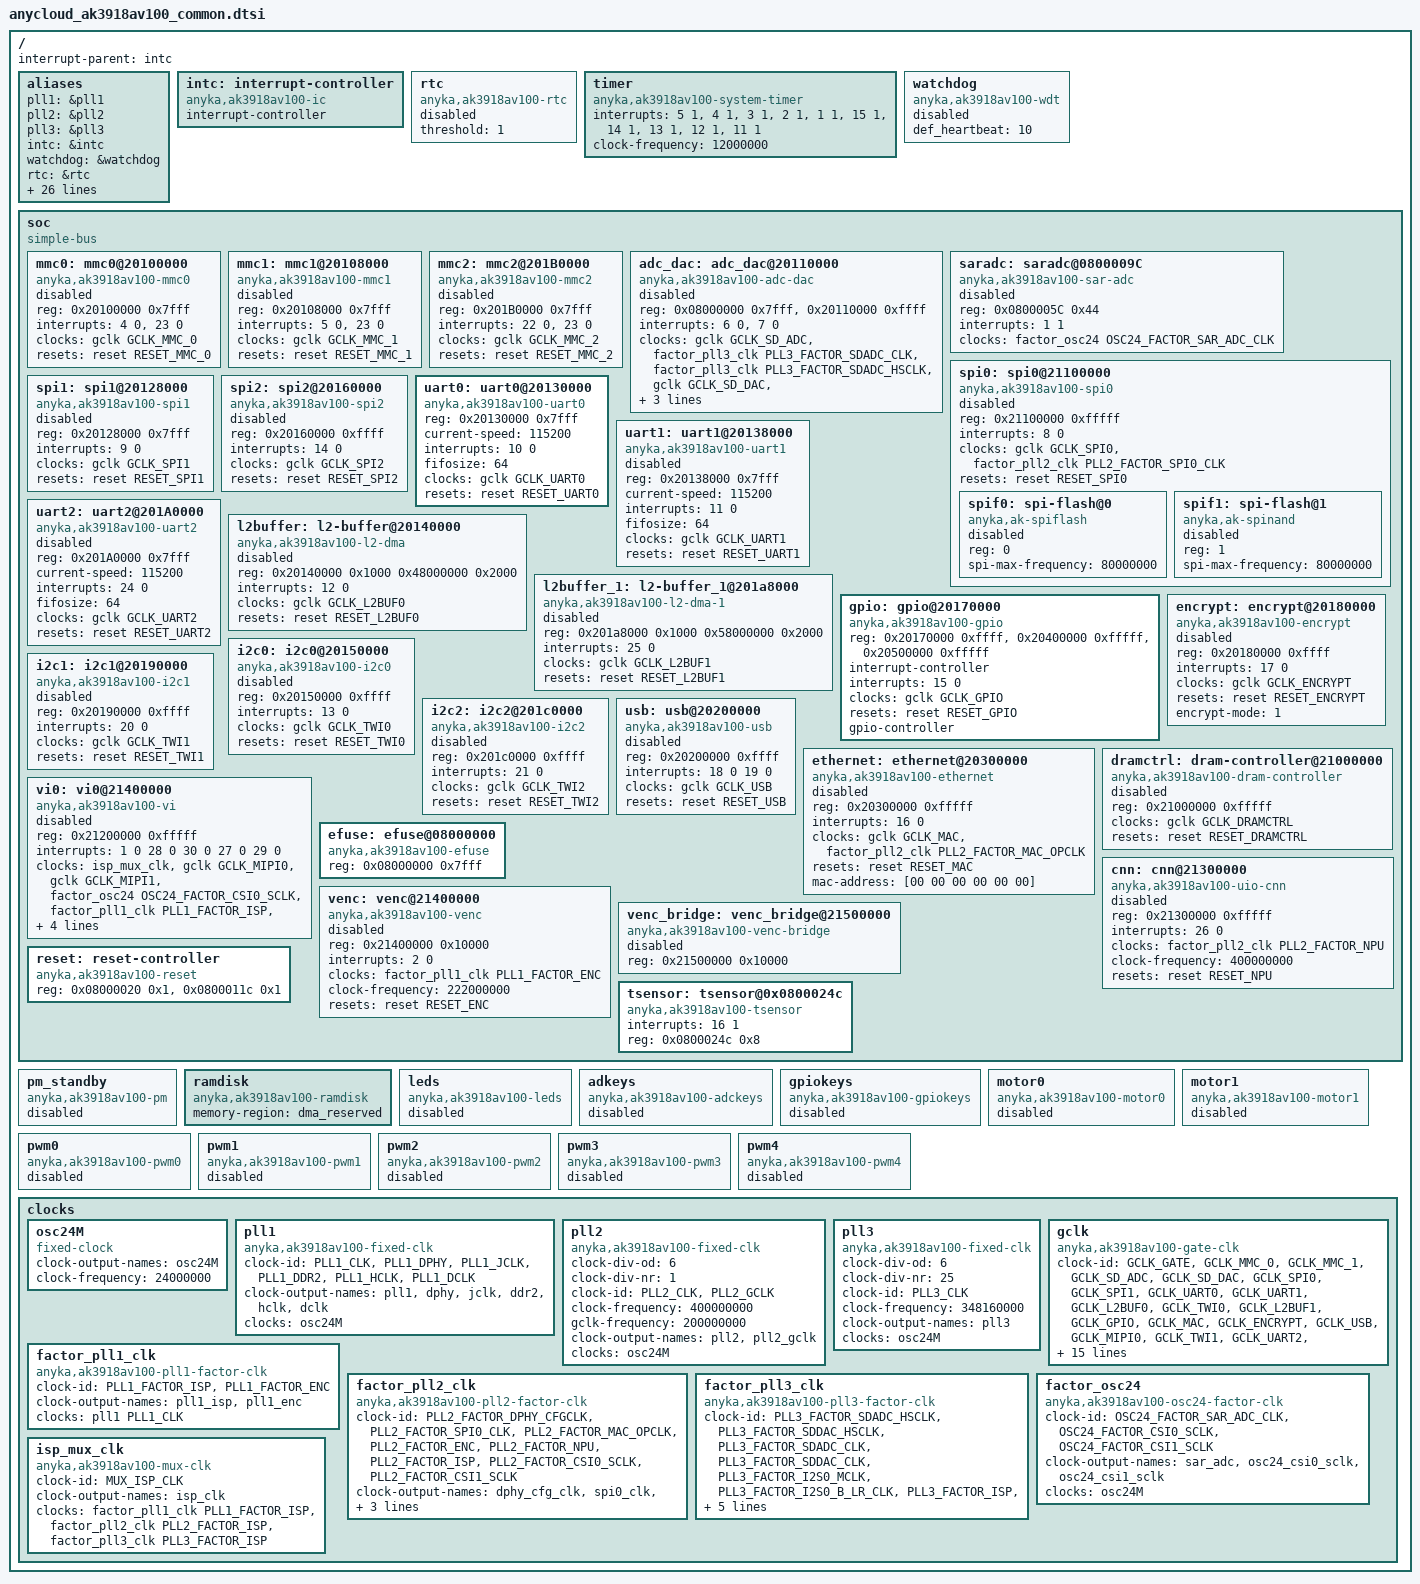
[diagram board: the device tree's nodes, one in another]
/*
 * ak3918av100 SoC
 *
 * Copyright (C) 2018 Anyka(Guangzhou) Microelectronics Technology Co., Ltd.
 *
 * This program is free software; you can redistribute it and/or modify
 * it under the terms of the GNU General Public License as published by
 * the Free Software Foundation; either version 2 of the License, or
 * (at your option) any later version.
 *
 * This program is distributed in the hope that it will be useful,
 * but WITHOUT ANY WARRANTY; without even the implied warranty of
 * MERCHANTABILITY or FITNESS FOR A PARTICULAR PURPOSE.  See the
 * GNU General Public License for more details.
 */
#include <dt-bindings/gpio/gpio.h>
#include <dt-bindings/clock/ak3918av100_clock.h>
#include <dt-bindings/hwmon/ina2xx.h>

/ {
    #address-cells = <1>;
    #size-cells = <1>;

    interrupt-parent = <&intc>;

    aliases {
        pll1 = &pll1;
        pll2 = &pll2;
        pll3 = &pll3;
        intc = &intc;
        watchdog = &watchdog;
        rtc = &rtc;
        pwm0 = &pwm0;
        pwm1 = &pwm1;
        pwm2 = &pwm2;
        pwm3 = &pwm3;
        pwm4 = &pwm4;
        gpio = &gpio;
        uart0 = &uart0;
        uart1 = &uart1;
        uart2 = &uart2;
        spi0 = &spi0;
        spi1 = &spi1;
        spi2 = &spi2;
        mmc0 = &mmc0;
        mmc1 = &mmc1;
        mmc2 = &mmc2;
        i2c0 = &i2c0;
        i2c1 = &i2c1;
        i2c2 = &i2c2;
        motor0 = &motor0;
        motor1 = &motor1;
        usb = &usb;
        leds = &leds;
        adkeys = &adkeys;
        gpiokeys = &gpiokeys;
        ethernet0 = &ethernet;
        pm_standby = &pm_standby;
    };

    intc: interrupt-controller {
        compatible = "anyka,ak3918av100-ic";
        interrupt-controller;
        #interrupt-cells = <2>;
    };

    rtc: rtc {
        compatible = "anyka,ak3918av100-rtc";
		/*
		 * under_voltage_detection
		 * 
		 * threshold:
		 * 0: reset when VDDIO drops below 2.79V,
		 *     and the reset will be deasserted when VDDIO reaches 3.0V
		 * 1: reset when VDDIO drops below 2.65V,
		 *     and the reset will be deasserted when VDDIO reaches 2.86V
		 * 2: reset when VDDIO drops below 2.55V,
		 *     and the reset will be deasserted when VDDIO reaches 2.78V
		 * 3: reset when VDDIO drops below 2.46V,
		 *     and the reset will be deasserted when VDDIO reaches 2.68V
		 */
		threshold = <1>;
        status = "disable";
    };

    timer {
        compatible = "anyka,ak3918av100-system-timer";
        interrupts = <5 1>,  // timer0, TOP_INT Interrupt Mask (Address: 0x0800,002C) bit5
                     <4 1>,  // timer1, TOP_INT Interrupt Mask (Address: 0x0800,002C) bit4
                     <3 1>,  // timer2, TOP_INT Interrupt Mask (Address: 0x0800,002C) bit3
                     <2 1>,  // timer3, TOP_INT Interrupt Mask (Address: 0x0800,002C) bit2
                     <1 1>,  // timer4, TOP_INT Interrupt Mask (Address: 0x0800,002C) bit1
                     <15 1>, // timer5, TOP_INT Interrupt Mask (Address: 0x0800,002C) bit15
                     <14 1>, // timer6, TOP_INT Interrupt Mask (Address: 0x0800,002C) bit14
                     <13 1>, // timer7, TOP_INT Interrupt Mask (Address: 0x0800,002C) bit13
                     <12 1>, // timer8, TOP_INT Interrupt Mask (Address: 0x0800,002C) bit12
                     <11 1>; // timer9, TOP_INT Interrupt Mask (Address: 0x0800,002C) bit11
        clock-frequency = <12000000>;
        status = "okay";
    };

    watchdog: watchdog {
        compatible = "anyka,ak3918av100-wdt";
        /*max feed dog time = 357s, default setting time = 10s. */
        def_heartbeat = <10>;
        status = "disable";
    };

    soc: soc {
        compatible = "simple-bus";
        #address-cells = <1>;
        #size-cells = <1>;
        ranges;

        mmc0: mmc0@20100000 {
            compatible = "anyka,ak3918av100-mmc0";
            reg = <0x20100000 0x7fff>;
            /* 
             * Bank0
             * 0x08000024 bit[4]    MCI/SD/SDIO Controller 0 Interrupt
             * 0x08000024 bit[23]   SD Plugin-Plugoff Interrupt
             */
            interrupts = <4 0>,<23 0>;
            clocks = <&gclk GCLK_MMC_0>;
            clock-names   = "mmc0";
            resets	  = <&reset RESET_MMC_0>;
            reset-names   = "mmc0"; /* same as node name */
            status = "disable";
        };

        mmc1: mmc1@20108000 {
            compatible = "anyka,ak3918av100-mmc1";
            /* 
             * Bank0
             * 0x08000024 bit[5]    MCI/SD/SDIO Controller 1 Interrupt
             * 0x08000024 bit[23]   SD Plugin-Plugoff Interrupt
             */
            reg = <0x20108000 0x7fff>;
            interrupts = <5 0>, <23 0>;
            clocks = <&gclk GCLK_MMC_1>;
            clock-names   = "mmc1_gclk";
            resets	  = <&reset RESET_MMC_1>;
            reset-names   = "mmc1"; /* same as node name */
            status = "disable";
        };

        mmc2: mmc2@201B0000 {
            compatible = "anyka,ak3918av100-mmc2";
            reg = <0x201B0000 0x7fff>;
            /* 
             * Bank0
             * 0x08000024 bit[22]    MCI/SD/SDIO Controller 2 Interrupt
             * 0x08000024 bit[23]   SD Plugin-Plugoff Interrupt
             */
            interrupts = <22 0>,<23 0>;
            clocks = <&gclk GCLK_MMC_2>;
            clock-names   = "mmc2_gclk";
            resets	  = <&reset RESET_MMC_2>;
            reset-names   = "mmc2"; /* same as node name */
            status = "disable";
        };

        adc_dac: adc_dac@20110000 {
            compatible = "anyka,ak3918av100-adc-dac";
            reg = <0x08000000 0x7fff>,
                  <0x20110000 0xffff>;
             /* 
             * Bank0
             * 0x08000024 bit[6]  Audio DAC Controller Interrupt
             * 0x08000024 bit[7] Audio ADC Controller Interrupt
             */
            interrupts = <6 0>,<7 0>;
            clocks =
                <&gclk GCLK_SD_ADC>,          //sdadc_gclk
                <&factor_pll3_clk PLL3_FACTOR_SDADC_CLK>,   //sdadc_clk
                <&factor_pll3_clk PLL3_FACTOR_SDADC_HSCLK>,   //sdadchs_clk
                <&gclk GCLK_SD_DAC>,          //sddac_gclk
                <&factor_pll3_clk PLL3_FACTOR_SDDAC_CLK>,   //sddac_clk
                <&factor_pll3_clk PLL3_FACTOR_SDDAC_HSCLK>;   //sddachs_clk
  
            clock-names =
                "sdadc_gclk",
                "sdadc_clk",
                "sdadchs_clk",
                "sddac_gclk",
                "sddac_clk",
                "sddachs_clk";

            resets = <&reset RESET_SD_ADC>,
                     <&reset RESET_SD_DAC>;
            reset-names   = "sdadc",
                            "sddac";
          
            status = "disable";
        };

        saradc: saradc@0800009C {
            compatible = "anyka,ak3918av100-sar-adc";
            reg = <0x0800005C 0x44>;
            /*
             * Bank1
             * 0x0800002c [0]:sar_adc_int_en 
             */
            interrupts = <1 1>;
            clocks = <&factor_osc24 OSC24_FACTOR_SAR_ADC_CLK>;
            status = "disable";
        };
        
        spi0: spi0@21100000 {
            compatible = "anyka,ak3918av100-spi0";
            reg = <0x21100000 0xfffff>;
            /*
             * Bank0
             * 0x08000024 [8] SFC --- Fast SPI
             */
            interrupts = <8 0>;
            clocks = <&gclk GCLK_SPI0>,
                     <&factor_pll2_clk PLL2_FACTOR_SPI0_CLK>;
            clock-names = "spi0_gclk",
                          "spi0_bus"; 

            resets = <&reset RESET_SPI0>;
            reset-names   = "spi0";

            #address-cells = <1>;
            #size-cells = <0>;
            status = "disable";

            spif0:spi-flash@0 {
                compatible = "anyka,ak-spiflash";
                reg = <0>; /* Chip select 0 */
                spi-max-frequency = <80000000>;
                status = "disable";
                #address-cells = <1>;
                #size-cells = <0>;
            };

            spif1:spi-flash@1 {
                compatible = "anyka,ak-spinand";
                reg = <1>; /* Chip select 1 */
                spi-max-frequency = <80000000>;
                status = "disable";
            };
        };

        spi1: spi1@20128000 {
            compatible = "anyka,ak3918av100-spi1";
            reg = <0x20128000 0x7fff>;
            /*
             * Bank0
             * 0x08000024 [9] SPI 1 Interrupt
             */
            interrupts = <9 0>;
            clocks = <&gclk GCLK_SPI1>;
            clock-names = "spi1_gclk";
            resets = <&reset RESET_SPI1>;
            reset-names   = "spi1";

            #address-cells = <1>;
            #size-cells = <0>;
            status = "disable";
        };

        spi2: spi2@20160000 {
            compatible = "anyka,ak3918av100-spi2";
            reg = <0x20160000 0xffff>;
            /*
             * Bank0
             * 0x08000024 [14] SPI 2 Interrupt
             */
            interrupts = <14 0>;
            clocks = <&gclk GCLK_SPI2>;
            clock-names = "spi2_gclk";
            resets = <&reset RESET_SPI2>;
            reset-names   = "spi2";

            #address-cells = <1>;
            #size-cells = <0>;
            status = "disable";
        };

        uart0: uart0@20130000 {
            compatible = "anyka,ak3918av100-uart0";
            reg = <0x20130000 0x7fff>;
            current-speed = <115200>;
            /*
             * Bank0
             * 0x08000024 [10] UART 0 Interrupt
             */
            interrupts = <10 0>;
            fifosize = <64>;

            clocks = <&gclk GCLK_UART0>;
            clock-names = "uart0_gclk";
            resets = <&reset RESET_UART0>;
            reset-names   = "uart0";
            
            status = "okay";
        };

        uart1: uart1@20138000 {
            compatible = "anyka,ak3918av100-uart1";
            reg = <0x20138000 0x7fff>;
            current-speed = <115200>;
            /*
             * Bank0
             * 0x08000024 [11] UART 1 Interrupt
             */
            interrupts = <11 0>;
            fifosize = <64>;

            clocks = <&gclk GCLK_UART1>;
            clock-names = "uart1_gclk";
            resets = <&reset RESET_UART1>;
            reset-names   = "uart1";

            status = "disable";
        };

        uart2: uart2@201A0000 {
            compatible = "anyka,ak3918av100-uart2";
            reg = <0x201A0000 0x7fff>;
            current-speed = <115200>;
            /*
             * Bank0
             * 0x08000024 [24] UART 2 Interrupt
             */
            interrupts = <24 0>;
            fifosize = <64>;

            clocks = <&gclk GCLK_UART2>;
            clock-names = "uart2_gclk";
            resets = <&reset RESET_UART2>;
            reset-names   = "uart2";

            status = "disable";
        };

        l2buffer: l2-buffer@20140000 {
            compatible = "anyka,ak3918av100-l2-dma";
            reg = <0x20140000 0x1000
                   0x48000000 0x2000>;
            /*
             * Bank0
             * 0x08000024 [12] L2-Buffer0 Interrupt
             */
            interrupts = <12 0>;
            
            clocks = <&gclk GCLK_L2BUF0>;
            clock-names = "l2buffer0_gclk";
            resets = <&reset RESET_L2BUF0>;
            reset-names   = "l2buffer0";

            status = "disable";
        };
        
        l2buffer_1: l2-buffer_1@201a8000 {
            compatible = "anyka,ak3918av100-l2-dma-1";
            reg = <0x201a8000 0x1000
                   0x58000000 0x2000>;
            /*
             * Bank0
             * 0x08000024 [25] L2-Buffer1 Interrupt
             */
            interrupts = <25 0>;

            clocks = <&gclk GCLK_L2BUF1>;
            clock-names = "l2buffer1_gclk";
            resets = <&reset RESET_L2BUF1>;
            reset-names   = "l2buffer_1";

            status = "disable";
        };

        gpio: gpio@20170000 {
            compatible = "anyka,ak3918av100-gpio";
            reg = <0x20170000 0xffff>,
            <0x20400000 0xfffff>,    /* mipi0 */
            <0x20500000 0xfffff>;    /* mipi1 */

            interrupt-controller;
            #interrupt-cells = <2>;
            /*
             * Bank0
             * 0x08000024 [15] GPIO Interrupt
             */
            interrupts = <15 0>;

            clocks = <&gclk GCLK_GPIO>;
            clock-names = "gpio_gclk";
            resets = <&reset RESET_GPIO>;
            reset-names   = "gpio";

            gpio-controller;
            #gpio-cells = <2>;
            status = "okay";
        };

        encrypt: encrypt@20180000 {
            compatible = "anyka,ak3918av100-encrypt";
            reg = <0x20180000 0xffff>;
            interrupts = <17 0>;
  
            clocks = <&gclk GCLK_ENCRYPT>;
            clock-names = "encrypt_gclk";
            resets = <&reset RESET_ENCRYPT>;
            reset-names   = "encrypt";

            /*
            * encrypt-mode
            * 0 = CRYPTO_SINGLE_GROUP_MODE ; 1 = CRYPTO_MULTI_GROUP_MODE
            */
            encrypt-mode = <1>;
            
            status = "disable";
        };

        i2c0: i2c0@20150000 {
            compatible = "anyka,ak3918av100-i2c0";
            reg = <0x20150000 0xffff>;
            /*
             * Bank0
             * 0x08000024 [13] I2C 0 Interrupt
             */
            interrupts = <13 0>;

            clocks = <&gclk GCLK_TWI0>;
            clock-names = "i2c0_gclk";
            resets = <&reset RESET_TWI0>;
            reset-names   = "i2c0";

            status = "disable";
        };

        i2c1: i2c1@20190000 {
            compatible = "anyka,ak3918av100-i2c1";
            reg = <0x20190000 0xffff>;
            /*
             * Bank0
             * 0x08000024 [20] I2C 1 Interrupt
             */
            interrupts = <20 0>;

            clocks = <&gclk GCLK_TWI1>;
            clock-names = "i2c1_gclk";
            resets = <&reset RESET_TWI1>;
            reset-names   = "i2c1";

            status = "disable";
        };

        i2c2: i2c2@201c0000 {
            compatible = "anyka,ak3918av100-i2c2";
            reg = <0x201c0000 0xffff>;
            /*
             * Bank0
             * 0x08000024 [21] I2C 2 Interrupt
             */          
            interrupts = <21 0>;

            clocks = <&gclk GCLK_TWI2>;
            clock-names = "i2c2_gclk";
            resets = <&reset RESET_TWI2>;
            reset-names   = "i2c2";

            #address-cells = <1>;
            #size-cells = <0>;
            status = "disable";
        };

        usb: usb@20200000 {
            compatible = "anyka,ak3918av100-usb";
            reg = <0x20200000 0xffff>;
            /*
             * Bank0
             * 0x08000024 [18] USB CPU Interrupt
             * 0x08000024 [19] USB DMA Interrupt
             */  
            interrupts = <18 0
                          19 0>;

            clocks = <&gclk GCLK_USB>;
            clock-names = "usb_gclk";
            resets = <&reset RESET_USB>;
            reset-names   = "usb";

            status = "disable";
        };

        ethernet: ethernet@20300000 {
            compatible = "anyka,ak3918av100-ethernet";
            reg = <0x20300000 0xfffff>;
            /*
             * Bank0
             * 0x08000024 [16] MAC Interrupt
             */  
            interrupts = <16 0>;
           
            clocks = <&gclk GCLK_MAC>,
                     <&factor_pll2_clk PLL2_FACTOR_MAC_OPCLK>; 
            clock-names = "mac_gclk", "mac0_opclk";
            resets = <&reset RESET_MAC>;
            reset-names   = "mac";

            mac-address = [00 00 00 00 00 00];
            status = "disable";
        };

        dramctrl:dram-controller@21000000 {
            compatible = "anyka,ak3918av100-dram-controller";
            reg = <0x21000000 0xfffff>;

            clocks = <&gclk GCLK_DRAMCTRL>;
            clock-names = "dramctrl_gclk";
            resets = <&reset RESET_DRAMCTRL>;
            reset-names   = "dramctrl";

            status = "disable";
        };

        vi0: vi0@21400000 {
            compatible = "anyka,ak3918av100-vi";
            reg = <0x21200000 0xfffff>;	/*image capreture controller*/
            /*
             * Bank0
             * 0x08000024 [1] ISP Interrupt
             * 0x08000024 [28] CSI0 normal Interrupt
             * 0x08000024 [30] CSI0 error occur Interrupt
             * 0x08000024 [27] CSI1 normal Interrupt
             * 0x08000024 [29] CSI1 error occur Interrupt
             */ 
            interrupts = <1 0
                          28 0
                          30 0
                          27 0
                          29 0>;
            clocks =  
                      /*<&factor_pll3_clk  PLL3_FACTOR_ISP>,*/
                      /*<&factor_pll2_clk  PLL2_FACTOR_ISP>,*/
                      <&isp_mux_clk>,
                      <&gclk GCLK_MIPI0>,
                      <&gclk GCLK_MIPI1>,
                      <&factor_osc24    OSC24_FACTOR_CSI0_SCLK>,
                      /*<&factor_osc24    OSC24_FACTOR_CSI1_SCLK>,*/
                      <&factor_pll1_clk  PLL1_FACTOR_ISP>,
                      <&factor_pll2_clk  PLL2_FACTOR_ISP>,
                      <&factor_pll3_clk  PLL3_FACTOR_ISP>,
                      <&factor_pll2_clk PLL2_FACTOR_DPHY_CFGCLK>;
            clock-names =   "isp_clk", 
                            "mipi0_gclk",
                            "mipi1_gclk",
                            "csi0_sclk",
                            /*"csi1_sclk",*/
                            "pll1_isp", 
                            "pll2_isp", 
                            "pll3_isp",
                            "pll2_dphy";

            resets = <&reset RESET_ISP>;
            reset-names   = "isp";

            status = "disable";
        };

        efuse: efuse@08000000 {
            compatible = "anyka,ak3918av100-efuse";
            reg = <0x08000000 0x7fff>;
            status = "okay";
        };

        cnn: cnn@21300000 {
            compatible = "anyka,ak3918av100-uio-cnn";
            reg = <0x21300000 0xfffff>;
            /*
             * Bank0
             * 0x08000024 [26] cnn interrupt
             */ 
            interrupts = <26 0>;
            clocks =  <&factor_pll2_clk  PLL2_FACTOR_NPU>;
            clock-names =  "pll2_npu";
            clock-frequency = <400000000>;

            resets = <&reset RESET_NPU>;
            reset-names   = "cnn";  /* same as node name */

            status = "disable";
        };

        venc: venc@21400000 {
            compatible = "anyka,ak3918av100-venc";
            reg = <0x21400000 0x10000>;
            interrupts = <2 0>;
            clocks =  <&factor_pll1_clk  PLL1_FACTOR_ENC>;
            clock-names =  "pll1_enc";
            clock-frequency = <222000000>;

            resets = <&reset RESET_ENC>;
            reset-names   = "venc";

            status = "disable";
         };

        venc_bridge: venc_bridge@21500000 {
            compatible = "anyka,ak3918av100-venc-bridge";
            reg = <0x21500000 0x10000>;
            status = "disable";
         };

        reset: reset-controller {
			compatible = "anyka,ak3918av100-reset";
            reg = <0x08000020 0x1>, <0x0800011c 0x1>;
			#reset-cells = <1>;
		};
        
        tsensor:tsensor@0x0800024c {
			compatible = "anyka,ak3918av100-tsensor";
            // tsensor, TOP_INT Interrupt Mask (Address: 0x0800,002C) bit16
            interrupts = <16 1>; 
            reg = <0x0800024c 0x8>;
            status = "okay";
        };
    };

    pm_standby: pm_standby {
        compatible = "anyka,ak3918av100-pm";
        status = "disable";
    };

    ramdisk:ramdisk{
        compatible = "anyka,ak3918av100-ramdisk";
        memory-region = <&dma_reserved>;
        status = "okay";
    };

    leds: leds {
        compatible = "anyka,ak3918av100-leds";
        status = "disable";
    };

    adkeys: adkeys {
        compatible = "anyka,ak3918av100-adckeys";
        status = "disable";
    };

    gpiokeys: gpiokeys {
        compatible = "anyka,ak3918av100-gpiokeys";
        status = "disable";
    };

    motor0: motor0 {
        compatible = "anyka,ak3918av100-motor0";
        status = "disable";
    };

    motor1: motor1 {
        compatible = "anyka,ak3918av100-motor1";
        status = "disable";
    };

    pwm0: pwm0 {
        compatible = "anyka,ak3918av100-pwm0";
        #pwm-cells = <2>;
        status = "disable";
    };

    pwm1: pwm1 {
        compatible = "anyka,ak3918av100-pwm1";
        #pwm-cells = <2>;
        status = "disable";
    };

    pwm2: pwm2 {
        compatible = "anyka,ak3918av100-pwm2";
        #pwm-cells = <2>;
        status = "disable";
    };

    pwm3: pwm3 {
        compatible = "anyka,ak3918av100-pwm3";
        #pwm-cells = <2>;
        status = "disable";
    };

    pwm4: pwm4 {
        compatible = "anyka,ak3918av100-pwm4";
        #pwm-cells = <2>;
        status = "disable";
    };

    clocks {
          osc24M: osc24M {
            compatible = "fixed-clock";
            #clock-cells = <0>;
            clock-output-names = "osc24M";
            clock-frequency = <24000000>;
        };

        pll1: pll1 {
            /*   
             *  PLL1 is configed in boot setting, and can't be configed in kernel.
             *  ReadOnly
             *
             *  DPHY:   DDR PHY source clock frequency
             *  JCLK:   CPU opreating clock
             *  DDR2:   DDR2 clock frequency
             *  HCLK:   CPU bus frequency
             *  DCLK:   memory controller working clock, equal to HCLK
             */
            compatible = "anyka,ak3918av100-fixed-clk";
            #clock-cells = <1>;
            clock-id = <PLL1_CLK>, <PLL1_DPHY>, <PLL1_JCLK>, <PLL1_DDR2>,
                         <PLL1_HCLK>,<PLL1_DCLK>;
            clock-output-names = "pll1","dphy","jclk", "ddr2",
                                    "hclk","dclk";
            clocks = <&osc24M>;
        };

        pll2: pll2 {
            compatible = "anyka,ak3918av100-fixed-clk";
            #clock-cells = <1>;
            clock-div-od = <6>;
            clock-div-nr = <1>;  //nf = 100
            clock-id = <PLL2_CLK>, <PLL2_GCLK>;
            clock-frequency = <400000000>;
            gclk-frequency  = <200000000>;
            clock-output-names = "pll2","pll2_gclk";
            clocks = <&osc24M>;
        };

     
        pll3: pll3 {
            compatible = "anyka,ak3918av100-fixed-clk";
            #clock-cells = <0>;
            clock-div-od = <6>;
            clock-div-nr = <25>; /* nf = 2176 */
            clock-id = <PLL3_CLK>;
            clock-frequency = <348160000>;
            clock-output-names = "pll3";
            clocks = <&osc24M>;
        };


        gclk: gclk{
            compatible = "anyka,ak3918av100-gate-clk";
            #clock-cells = <1>;
            /*
            * GCLK_GATE and GCLK_DRAMCTRL, software cannot config it.
            */
            clock-id =  <GCLK_GATE>, 
                        <GCLK_MMC_0>,   <GCLK_MMC_1>,   <GCLK_SD_ADC>,  <GCLK_SD_DAC>,  <GCLK_SPI0>, 
                        <GCLK_SPI1>,    <GCLK_UART0>,   <GCLK_UART1>,   <GCLK_L2BUF0>,  <GCLK_TWI0>, 
                        <GCLK_L2BUF1>,  <GCLK_GPIO>,    <GCLK_MAC>,     <GCLK_ENCRYPT>,  <GCLK_USB>,
                        <GCLK_MIPI0>,   <GCLK_TWI1>,    <GCLK_UART2>,   <GCLK_MIPI1>,   <GCLK_SPI2>, 
                        <GCLK_MMC_2>,   <GCLK_TWI2>,    <GCLK_DRAMCTRL>,<GCLK_DDR_PHY>;
                        
            clock-ctrlbit = <0>, 
                            <1>, <2>, <3>, <4>, <5>, 
                            <6>, <7>, <8>, <9>, <10>, 
                            <11>, <12>,<13>, <14>, <15>,
                            <16>, <17>, <18>, <18>, <20>,
                            <21>, <22>, <24>, <25>;

            clock-output-names = "gate",
                                 "mmc0_gclk", "mmc1_gclk", "sdadc_gclk",   "sddac_gclk", "spi0_gclk",   
                                 "spi1_gclk", "uart0_gclk", "uart1_gclk", "l2buffer0_gclk", "i2c0_gclk", 
                                 "l2buffer1_gclk", "gpio_gclk", "mac_gclk", "encrypt_gclk", "usb_gclk", 
                                 "mipi0_gclk","i2c1_gclk", "uart2_gclk", "mipi1_gclk", "spi2_gclk",
                                 "mmc2_gclk", "i2c2_gclk", "dramctrl_gclk", "ddrphy_gclk";
            clocks = <&pll2 PLL2_GCLK>;
        };

        factor_pll1_clk: factor_pll1_clk {
            compatible = "anyka,ak3918av100-pll1-factor-clk";
            #clock-cells = <1>;
            clock-id =  <PLL1_FACTOR_ISP>, <PLL1_FACTOR_ENC>;
            clock-output-names = "pll1_isp", "pll1_enc";
            clocks = <&pll1 PLL1_CLK>; 
        };

        factor_pll2_clk: factor_pll2_clk {
            compatible = "anyka,ak3918av100-pll2-factor-clk";
            #clock-cells = <1>;
            clock-id =  <PLL2_FACTOR_DPHY_CFGCLK>, 
                        <PLL2_FACTOR_SPI0_CLK>,<PLL2_FACTOR_MAC_OPCLK>,
                        <PLL2_FACTOR_ENC>,<PLL2_FACTOR_NPU>,<PLL2_FACTOR_ISP>,
                        <PLL2_FACTOR_CSI0_SCLK>,<PLL2_FACTOR_CSI1_SCLK>;
            clock-output-names = "dphy_cfg_clk",
                                 "spi0_clk", "mac_opclk",
                                  "pll2_enc", "pll2_npu", "pll2_isp",
                                  "pll2_csi0_sclk", "pll2_csi1_sclk";
            clocks = <&pll2 PLL2_CLK>;
        };

        factor_pll3_clk: factor_pll3_clk {
            compatible = "anyka,ak3918av100-pll3-factor-clk";
            #clock-cells = <1>;
            clock-id =  <PLL3_FACTOR_SDADC_HSCLK>, <PLL3_FACTOR_SDDAC_HSCLK>, 
                        <PLL3_FACTOR_SDADC_CLK>, <PLL3_FACTOR_SDDAC_CLK>, 
                        <PLL3_FACTOR_I2S0_MCLK>, <PLL3_FACTOR_I2S0_B_LR_CLK>, <PLL3_FACTOR_ISP>,<PLL3_FACTOR_NPU>,<PLL3_FACTOR_ENC>;
            clock-output-names = "sdadchs", "sddachs", 
                                 "sdadc", "sddac",
                                 "i2s0_mclk", "i2s0_b_lr_clk","pll3_isp","pll3_npu","pll3_enc";
            clocks = <&pll3>;
        };
    
        factor_osc24: factor_osc24 {
            compatible = "anyka,ak3918av100-osc24-factor-clk";
            #clock-cells = <1>;
            clock-id = <OSC24_FACTOR_SAR_ADC_CLK>, <OSC24_FACTOR_CSI0_SCLK>, <OSC24_FACTOR_CSI1_SCLK>;
            clock-output-names = "sar_adc", "osc24_csi0_sclk", "osc24_csi1_sclk";
            clocks = <&osc24M>;
        };
        
        isp_mux_clk:isp_mux_clk{
            compatible = "anyka,ak3918av100-mux-clk";
            #clock-cells = <0>;
            clock-id = <MUX_ISP_CLK>;
            clock-output-names = "isp_clk";
            clocks = <&factor_pll1_clk PLL1_FACTOR_ISP>, <&factor_pll2_clk PLL2_FACTOR_ISP>, <&factor_pll3_clk PLL3_FACTOR_ISP>;
        };

        /*
        npu_mux_clk:npu_mux_clk{
            compatible = "anyka,ak3918av100-mux-clk";
            #clock-cells = <1>;
            clock-id = <MUX_NPU_CLK>;
            clock-output-names = "npu_clk";
            clocks = <&pll1>, <&pll2>, <&pll3>;
        }

        enc_mux_clk:enc_mux_clk{
            compatible = "anyka,ak3918av100-mux-clk";
            #clock-cells = <1>;
            clock-id = <MUX_ENC_CLK>;
            clock-output-names = "enc_clk";
            clocks = <&pll1>, <&pll2>, <&pll3>;
        }
        */
        /*
        isp_npu_enc_mux_clk:isp_npu_enc_mux_clk{
            compatible = "anyka,ak3918av100-mux-clk";
            #clock-cells = <0>;
            clock-id = <MUX_ISP_CLK>,
                       <MUX_NPU_CLK>,
                       <MUX_NPU_CLK>;
            clock-output-names = "isp_clk",
                                 "npu_clk",
                                 "enc_clk";
           clocks = <&pll1 PLL1_DPHY>, 
                    <&pll2>, 
                    <&pll3>;
        };

        csi_sclk_mux_clk:csi_sclk_mux_clk{
            compatible = "anyka,ak3918av100-mux-clk";
            #clock-cells = <0>;

            clock-id = <MUX_CSI0_CLK>,
                       <MUX_CSI1_CLK>;
            clock-output-names = "csi0_sclk",
                                 "csi1_sclk";
                                
            clocks =  <&pll1 PLL1_DPHY>, 
                      <&pll2>, 
                      <&pll3>,
                      <&osc24M>;
        };
        */
    };
};

/*
* snd-dev:
*   SND_CARD_DAC_PLAYBACK = 0
*   SND_CARD_ADC_CAPTURE = 1
*   SND_CARD_DAC_LOOPBACK = 2
*   SND_CARD_I2S0_SEND = 3
*   SND_CARD_I2S0_RECV = 4
*   SND_CARD_I2S0_LOOPBACK = 5
*   SND_CARD_I2S1_RECV = 6
*   SND_CARD_PDM_RECV = 7
* snd-type:
*   AK_PCM_DEV_PLAYBACK = 0
*   AK_PCM_DEV_CAPTURE = 1
*   AK_PCM_DEV_LOOPBACK = 2
* snd-idx:
*   for the sample snd-type, make diff idx to re-name them
* !!!Please notice this configration as same as the ak_pcm_def.h!!!
*/
#define SND_CARD_DAC_PLAYBACK   0
#define SND_CARD_ADC_CAPTURE    1
#define SND_CARD_DAC_LOOPBACK   2
#define SND_CARD_I2S0_SEND      3
#define SND_CARD_I2S0_RECV      4
#define SND_CARD_I2S0_LOOPBACK  5
#define SND_CARD_I2S1_RECV      6
#define SND_CARD_PDM_RECV       7

#define AK_PCM_DEV_PLAYBACK     0
#define AK_PCM_DEV_CAPTURE      1
#define AK_PCM_DEV_LOOPBACK     2
